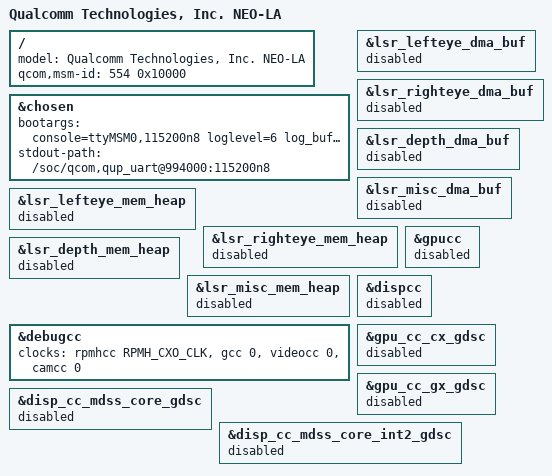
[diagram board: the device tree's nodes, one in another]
#include "neo.dtsi"

/ {
	model = "Qualcomm Technologies, Inc. NEO-LA";
	qcom,msm-id = <554 0x10000>;
};

&chosen {
	bootargs = "console=ttyMSM0,115200n8 loglevel=6 log_buf_len=256K kernel.panic_on_rcu_stall=1 loop.max_part=7 pcie_ports=compat service_locator.enable=1 msm_rtb.filter=0x237 allow_mismatched_32bit_el0 kasan=off rcupdate.rcu_expedited=1 rcu_nocbs=0-7 pstore.compress=none kpti=off swiotlb=noforce cgroup.memory=nokmem,nosocket allow_file_spec_access cpufreq.default_governor=performance disable_dma32=on ftrace_dump_on_oops";

	stdout-path = "/soc/qcom,qup_uart@994000:115200n8";
};

&lsr_lefteye_dma_buf {
	status = "disabled";
};

&lsr_righteye_dma_buf {
	status = "disabled";
};

&lsr_depth_dma_buf {
	status = "disabled";
};

&lsr_misc_dma_buf {
	status = "disabled";
};

&lsr_lefteye_mem_heap {
	status = "disabled";
};

&lsr_righteye_mem_heap {
	status = "disabled";
};

&lsr_depth_mem_heap {
	status = "disabled";
};

&lsr_misc_mem_heap {
	status = "disabled";
};

&gpucc {
	status = "disabled";
};

&dispcc {
	status = "disabled";
};

&debugcc {
	/delete-property/ qcom,gpucc;
	/delete-property/ qcom,dispcc;
	clock-names = "xo_clk_src",
			"gcc",
			"videocc",
			"camcc";
	clocks = <&rpmhcc RPMH_CXO_CLK>,
		<&gcc 0>,
		<&videocc 0>,
		<&camcc 0>;
};

&gpu_cc_cx_gdsc {
	status = "disabled";
};

&gpu_cc_gx_gdsc {
	status = "disabled";
};

&disp_cc_mdss_core_gdsc {
	status = "disabled";
};

&disp_cc_mdss_core_int2_gdsc {
	status = "disabled";
};
